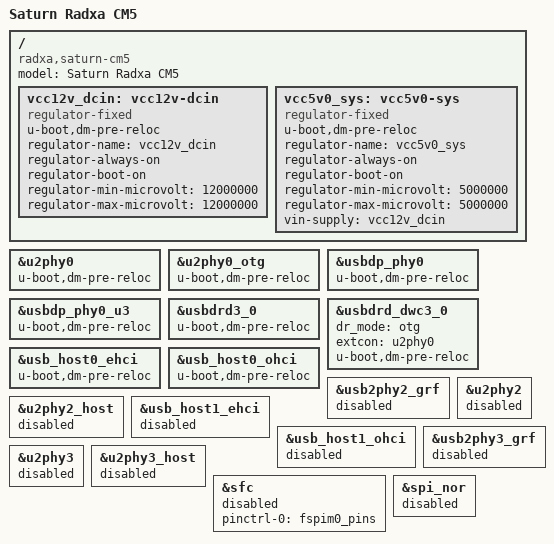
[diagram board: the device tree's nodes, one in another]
// SPDX-License-Identifier: (GPL-2.0+ OR MIT)
/*
 * Copyright (c) 2023 Rockchip Electronics Co., Ltd
 *
 */

/dts-v1/;
#include "rk3588.dtsi"
#include "rk3588-u-boot.dtsi"
#include <dt-bindings/input/input.h>

/ {
	model = "Saturn Radxa CM5";
	compatible = "radxa,saturn-cm5", "radxa,cm5", "rockchip,rk3588";

	vcc12v_dcin: vcc12v-dcin {
		u-boot,dm-pre-reloc;
		compatible = "regulator-fixed";
		regulator-name = "vcc12v_dcin";
		regulator-always-on;
		regulator-boot-on;
		regulator-min-microvolt = <12000000>;
		regulator-max-microvolt = <12000000>;
	};

	vcc5v0_sys: vcc5v0-sys {
		u-boot,dm-pre-reloc;
		compatible = "regulator-fixed";
		regulator-name = "vcc5v0_sys";
		regulator-always-on;
		regulator-boot-on;
		regulator-min-microvolt = <5000000>;
		regulator-max-microvolt = <5000000>;
		vin-supply = <&vcc12v_dcin>;
	};
};

&u2phy0 {
	status = "okay";
	u-boot,dm-pre-reloc;
};

&u2phy0_otg {
	status = "okay";
	u-boot,dm-pre-reloc;
};

&usbdp_phy0 {
	status = "okay";
	u-boot,dm-pre-reloc;
};

&usbdp_phy0_u3 {
	status = "okay";
	u-boot,dm-pre-reloc;
};

&usbdrd3_0 {
	status = "okay";
	u-boot,dm-pre-reloc;
};

&usbdrd_dwc3_0 {
	dr_mode = "otg";
	extcon = <&u2phy0>;
	status = "okay";
	u-boot,dm-pre-reloc;
};

&usb_host0_ehci {
	status = "okay";
	u-boot,dm-pre-reloc;
};

&usb_host0_ohci {
	status = "okay";
	u-boot,dm-pre-reloc;
};

&usb2phy2_grf {
	status = "disabled";
};

&u2phy2 {
	status = "disabled";
};

&u2phy2_host {
	status = "disabled";
};

&usb_host1_ehci {
	status = "disabled";
};

&usb_host1_ohci {
	status = "disabled";
};

&usb2phy3_grf {
	status = "disabled";
};

&u2phy3 {
	status = "disabled";
};

&u2phy3_host {
	status = "disabled";
};

&sfc {
	status = "disabled";
	pinctrl-names = "default";
	pinctrl-0 = <&fspim0_pins>;
};

&spi_nor {
	status = "disabled";
};
